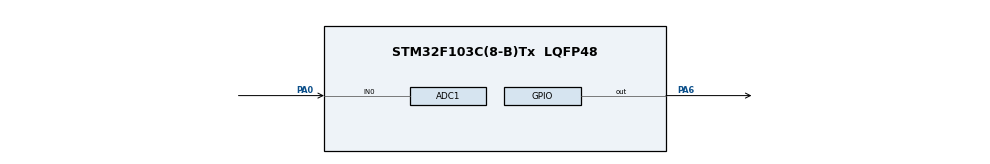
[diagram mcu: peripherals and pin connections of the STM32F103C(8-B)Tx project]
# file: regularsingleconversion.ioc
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ADC1.Channel-0\#ChannelRegularConversion=ADC_CHANNEL_0
ADC1.NbrOfConversionFlag=1
ADC1.Rank-0\#ChannelRegularConversion=1
ADC1.SamplingTime-0\#ChannelRegularConversion=ADC_SAMPLETIME_7CYCLES_5
ADC1.master=1
Mcu.Family=STM32F1
Mcu.Name=STM32F103C(8-B)Tx
Mcu.Package=LQFP48
NVIC.PriorityGroup=NVIC_PRIORITYGROUP_4
PA0-WKUP.Signal=ADCx_IN0
PA13.Mode=Serial_Wire
PA13.Signal=SYS_JTMS-SWDIO
PA14.Mode=Serial_Wire
PA14.Signal=SYS_JTCK-SWCLK
PA6.GPIO_ModeDefaultOutputPP=GPIO_MODE_OUTPUT_PP
PA6.GPIO_PuPd=GPIO_NOPULL
PA6.Signal=GPIO_Output
ProjectManager.HeapSize=0x200
ProjectManager.StackSize=0x400
ProjectManager.TargetToolchain=Makefile
RCC.APB1Freq_Value=8000000
RCC.APB2Freq_Value=8000000
SH.ADCx_IN0.0=ADC1_IN0,IN0
board=custom

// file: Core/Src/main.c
/* USER CODE BEGIN Header */
/**
  ******************************************************************************
  * @file           : main.c
  * @brief          : Main program body
  ******************************************************************************
  * @attention
  *
  * Copyright (c) 2026 STMicroelectronics.
  * All rights reserved.
  *
  * This software is licensed under terms that can be found in the LICENSE file
  * in the root directory of this software component.
  * If no LICENSE file comes with this software, it is provided AS-IS.
  *
  ******************************************************************************
  */
/* USER CODE END Header */
#include "main.h"

ADC_HandleTypeDef hadc1;

void SystemClock_Config(void);
static void MX_GPIO_Init(void);
static void MX_ADC1_Init(void);

int main(void)
{

  /* MCU Configuration--------------------------------------------------------*/

  /* Reset of all peripherals, Initializes the Flash interface and the Systick. */
  HAL_Init();

  /* Configure the system clock */
  SystemClock_Config();

  /* Initialize all configured peripherals */
  MX_GPIO_Init();
  MX_ADC1_Init();
  /* USER CODE BEGIN 2 */
  /* 板载 LED：蓝pill 上的 PC13，低电平点亮
     放在 USER CODE 区，CubeMX 重新生成代码时不会被覆盖 */
  __HAL_RCC_GPIOC_CLK_ENABLE();
  GPIO_InitTypeDef led_pc13 = {0};
  led_pc13.Pin = GPIO_PIN_13;
  led_pc13.Mode = GPIO_MODE_OUTPUT_PP;
  led_pc13.Pull = GPIO_NOPULL;
  led_pc13.Speed = GPIO_SPEED_FREQ_LOW;
  HAL_GPIO_Init(GPIOC, &led_pc13);

  /* 外接 LED：PA6。CubeMX 里被配成了开漏(OD)，开漏输出不了高电平，
     所以这里强制重新初始化为推挽输出(PP)，不依赖 .ioc 重新生成 */
  GPIO_InitTypeDef led_pa6 = {0};
  led_pa6.Pin = GPIO_PIN_6;
  led_pa6.Mode = GPIO_MODE_OUTPUT_PP;
  led_pa6.Pull = GPIO_NOPULL;
  led_pa6.Speed = GPIO_SPEED_FREQ_LOW;
  HAL_GPIO_Init(GPIOA, &led_pa6);

  /* ---- 上电自检：两个灯各闪 3 下，不读 ADC，纯 GPIO 翻转 ----
     调试用，确认硬件通路后再删掉这一段 */
  for (int i = 0; i < 3; i++)
  {
    HAL_GPIO_WritePin(GPIOA, GPIO_PIN_6, GPIO_PIN_SET);      /* PA6 亮 */
    HAL_GPIO_WritePin(GPIOC, GPIO_PIN_13, GPIO_PIN_RESET);   /* PC13 亮 */
    HAL_Delay(300);
    HAL_GPIO_WritePin(GPIOA, GPIO_PIN_6, GPIO_PIN_RESET);    /* PA6 灭 */
    HAL_GPIO_WritePin(GPIOC, GPIO_PIN_13, GPIO_PIN_SET);     /* PC13 灭 */
    HAL_Delay(300);
  }
  /* USER CODE END 2 */

  /* Infinite loop */
  /* USER CODE BEGIN WHILE */
  while (1)
  {
    /* 读取光敏模块的模拟输出 (AO → PA0 / ADC1_IN0) */
    HAL_ADC_Start(&hadc1);
    HAL_ADC_PollForConversion(&hadc1, HAL_MAX_DELAY);
    uint32_t adc_value = HAL_ADC_GetValue(&hadc1);

    /* 把 ADC 原始值换算成电压 (0 ~ 3.3V) */
    float voltage = adc_value * 3.3f / 4096.0f;

    /* 光敏模块的特性：环境越暗，AO 输出电压越高。
         voltage >  1.5V  → 判定为"暗" → 两个 LED 都点亮
         voltage <= 1.5V  → 判定为"亮" → 两个 LED 都熄灭
       PC13 是低电平点亮（板载），PA6 是高电平点亮（外接），所以两句电平相反。
       若你的 PA6 LED 是低电平点亮（接 3.3V 一侧），把 PA6 的 SET/RESET 对调 */
    if (voltage > 1.5f)
    {
      HAL_GPIO_WritePin(GPIOC, GPIO_PIN_13, GPIO_PIN_RESET);  /* 暗 → 板载灯亮（低电平点亮） */
      HAL_GPIO_WritePin(GPIOA, GPIO_PIN_6, GPIO_PIN_SET);     /* 暗 → PA6 灯亮（高电平点亮） */
    }
    else
    {
      HAL_GPIO_WritePin(GPIOC, GPIO_PIN_13, GPIO_PIN_SET);    /* 亮 → 板载灯灭 */
      HAL_GPIO_WritePin(GPIOA, GPIO_PIN_6, GPIO_PIN_RESET);   /* 亮 → PA6 灯灭 */
    }

    HAL_Delay(50);  /* 别刷太快，给 ADC 和眼睛一点时间 */
    /* USER CODE END WHILE */

  }
}

void SystemClock_Config(void)
{
  RCC_OscInitTypeDef RCC_OscInitStruct = {0};
  RCC_ClkInitTypeDef RCC_ClkInitStruct = {0};
  RCC_PeriphCLKInitTypeDef PeriphClkInit = {0};

  /** Initializes the RCC Oscillators according to the specified parameters
  * in the RCC_OscInitTypeDef structure.
  */
  RCC_OscInitStruct.OscillatorType = RCC_OSCILLATORTYPE_HSI;
  RCC_OscInitStruct.HSIState = RCC_HSI_ON;
  RCC_OscInitStruct.HSICalibrationValue = RCC_HSICALIBRATION_DEFAULT;
  RCC_OscInitStruct.PLL.PLLState = RCC_PLL_NONE;
  if (HAL_RCC_OscConfig(&RCC_OscInitStruct) != HAL_OK)
  {
    Error_Handler();
  }

  /** Initializes the CPU, AHB and APB buses clocks
  */
  RCC_ClkInitStruct.ClockType = RCC_CLOCKTYPE_HCLK|RCC_CLOCKTYPE_SYSCLK
                              |RCC_CLOCKTYPE_PCLK1|RCC_CLOCKTYPE_PCLK2;
  RCC_ClkInitStruct.SYSCLKSource = RCC_SYSCLKSOURCE_HSI;
  RCC_ClkInitStruct.AHBCLKDivider = RCC_SYSCLK_DIV1;
  RCC_ClkInitStruct.APB1CLKDivider = RCC_HCLK_DIV1;
  RCC_ClkInitStruct.APB2CLKDivider = RCC_HCLK_DIV1;

  if (HAL_RCC_ClockConfig(&RCC_ClkInitStruct, FLASH_LATENCY_0) != HAL_OK)
  {
    Error_Handler();
  }
  PeriphClkInit.PeriphClockSelection = RCC_PERIPHCLK_ADC;
  PeriphClkInit.AdcClockSelection = RCC_ADCPCLK2_DIV2;
  if (HAL_RCCEx_PeriphCLKConfig(&PeriphClkInit) != HAL_OK)
  {
    Error_Handler();
  }
}

static void MX_ADC1_Init(void)
{

  ADC_ChannelConfTypeDef sConfig = {0};

  /** Common config
  */
  hadc1.Instance = ADC1;
  hadc1.Init.ScanConvMode = ADC_SCAN_DISABLE;
  hadc1.Init.ContinuousConvMode = DISABLE;
  hadc1.Init.DiscontinuousConvMode = DISABLE;
  hadc1.Init.ExternalTrigConv = ADC_SOFTWARE_START;
  hadc1.Init.DataAlign = ADC_DATAALIGN_RIGHT;
  hadc1.Init.NbrOfConversion = 1;
  if (HAL_ADC_Init(&hadc1) != HAL_OK)
  {
    Error_Handler();
  }

  /** Configure Regular Channel
  */
  sConfig.Channel = ADC_CHANNEL_0;
  sConfig.Rank = ADC_REGULAR_RANK_1;
  sConfig.SamplingTime = ADC_SAMPLETIME_7CYCLES_5;
  if (HAL_ADC_ConfigChannel(&hadc1, &sConfig) != HAL_OK)
  {
    Error_Handler();
  }

}

static void MX_GPIO_Init(void)
{
  GPIO_InitTypeDef GPIO_InitStruct = {0};

  /* GPIO Ports Clock Enable */
  __HAL_RCC_GPIOA_CLK_ENABLE();

  /*Configure GPIO pin Output Level */
  HAL_GPIO_WritePin(GPIOA, GPIO_PIN_6, GPIO_PIN_RESET);

  /*Configure GPIO pin : PA6 */
  GPIO_InitStruct.Pin = GPIO_PIN_6;
  GPIO_InitStruct.Mode = GPIO_MODE_OUTPUT_OD;
  GPIO_InitStruct.Pull = GPIO_NOPULL;
  GPIO_InitStruct.Speed = GPIO_SPEED_FREQ_LOW;
  HAL_GPIO_Init(GPIOA, &GPIO_InitStruct);

}

void Error_Handler(void)
{
  __disable_irq();
  while (1)
  {
  }
}
